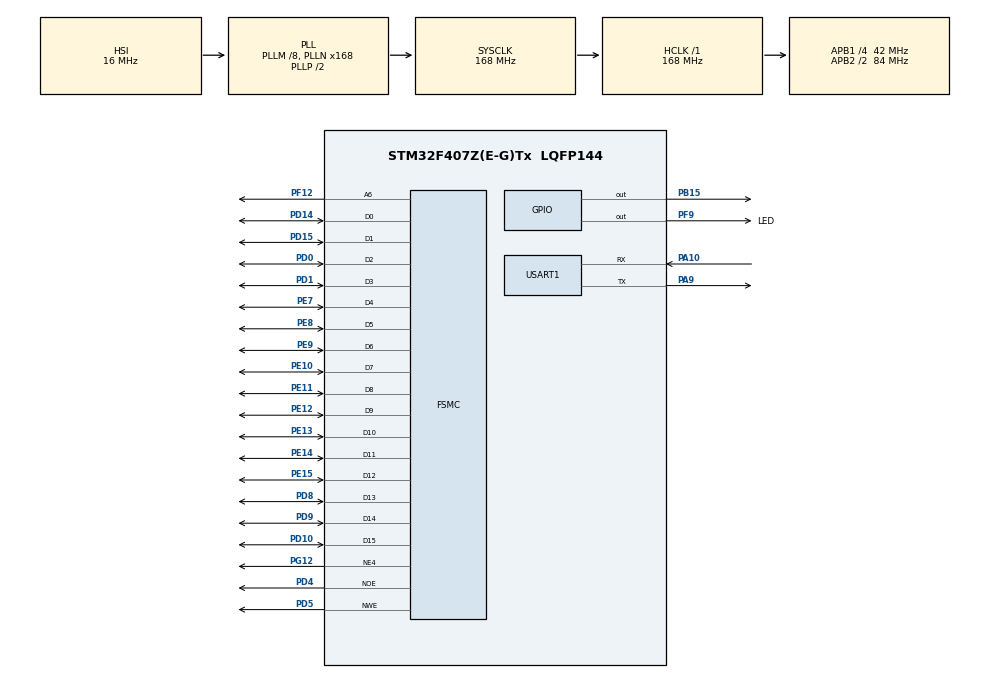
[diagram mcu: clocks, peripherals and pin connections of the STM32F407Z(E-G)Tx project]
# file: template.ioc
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Mcu.Family=STM32F4
PH0-OSC_IN.Signal=RCC_OSC_IN
RCC.CortexFreq_Value=168000000
SH.FSMC_D1_DA1.0=FSMC_D1,16b-d1
SH.FSMC_A6.0=FSMC_A6,A6_1
SH.FSMC_NWE.0=FSMC_NWE,Lcd1
SH.FSMC_D0_DA0.0=FSMC_D0,16b-d1
FSMC.ExtendedBusTurnAroundDuration1=0
PB15.Signal=GPIO_Output
RCC.SYSCLKSource=RCC_SYSCLKSOURCE_PLLCLK
ProjectManager.StackSize=0x400
Dma.USART1_TX.0.Priority=DMA_PRIORITY_LOW
Dma.USART1_TX.0.Direction=DMA_MEMORY_TO_PERIPH
RCC.HCLKFreq_Value=168000000
PD4.Signal=FSMC_NOE
RCC.APB2TimFreq_Value=168000000
PF12.Signal=FSMC_A6
PD0.Signal=FSMC_D2_DA2
PD8.Signal=FSMC_D13_DA13
RCC.AHBFreq_Value=168000000
PH0-OSC_IN.Mode=HSE-External-Oscillator
RCC.HSE_VALUE=25000000
PE13.Signal=FSMC_D10_DA10
SH.FSMC_D14_DA14.0=FSMC_D14,16b-d1
PC14-OSC32_IN.Mode=LSE-External-Oscillator
SH.FSMC_D10_DA10.0=FSMC_D10,16b-d1
PE9.Signal=FSMC_D6_DA6
PA14.Mode=Serial_Wire
SH.FSMC_D6_DA6.0=FSMC_D6,16b-d1
FSMC.BusTurnAroundDuration1=10
Dma.USART1_TX.0.PeriphDataAlignment=DMA_PDATAALIGN_BYTE
PE10.Signal=FSMC_D7_DA7
SH.FSMC_D5_DA5.0=FSMC_D5,16b-d1
SH.FSMC_D4_DA4.0=FSMC_D4,16b-d1
PH1-OSC_OUT.Mode=HSE-External-Oscillator
Mcu.Package=LQFP144
NVIC.DMA2_Stream7_IRQn=true\:0\:0\:false\:false\:true\:false\:true
SH.FSMC_D13_DA13.0=FSMC_D13,16b-d1
PA10.Signal=USART1_RX
Dma.USART1_TX.0.Instance=DMA2_Stream7
Dma.USART1_TX.0.FIFOMode=DMA_FIFOMODE_DISABLE
RCC.APB2CLKDivider=RCC_HCLK_DIV2
SH.FSMC_D3_DA3.0=FSMC_D3,16b-d1
RCC.APB1TimFreq_Value=84000000
SH.FSMC_D2_DA2.0=FSMC_D2,16b-d1
PE7.Signal=FSMC_D4_DA4
NVIC.USART1_IRQn=true\:0\:0\:false\:false\:true\:true\:true
Dma.Request0=USART1_TX
PD15.Signal=FSMC_D1_DA1
PG12.Signal=FSMC_NE4
FSMC.ExtendedAddressSetupTime1=9
PC15-OSC32_OUT.Mode=LSE-External-Oscillator
SH.FSMC_D12_DA12.0=FSMC_D12,16b-d1
Dma.USART1_TX.0.MemInc=DMA_MINC_ENABLE
Dma.USART1_TX.0.PeriphInc=DMA_PINC_DISABLE
PA10.Mode=Asynchronous
FSMC.ExtendedMode1=FSMC_EXTENDED_MODE_ENABLE
PD1.Signal=FSMC_D3_DA3
SH.FSMC_D9_DA9.0=FSMC_D9,16b-d1
PD9.Signal=FSMC_D14_DA14
PD5.Signal=FSMC_NWE
RCC.APB1CLKDivider=RCC_HCLK_DIV4
PC14-OSC32_IN.Signal=RCC_OSC32_IN
SH.FSMC_D8_DA8.0=FSMC_D8,16b-d1
PD10.Signal=FSMC_D15_DA15
PA13.Signal=SYS_JTMS-SWDIO
PA9.Mode=Asynchronous
ProjectManager.TargetToolchain=Makefile
FSMC.DataSetupTime1=60
PA9.Signal=USART1_TX
PF9.GPIO_Label=LED
PE11.Signal=FSMC_D8_DA8
PC15-OSC32_OUT.Signal=RCC_OSC32_OUT
SH.FSMC_D7_DA7.0=FSMC_D7,16b-d1
FSMC.ExtendedDataSetupTime1=8
Dma.USART1_TX.0.Mode=DMA_NORMAL
board=custom
PG12.Mode=NorPsramChipSelect4_1
RCC.VCOOutputFreq_Value=336000000
RCC.APB2Freq_Value=84000000
PE14.Signal=FSMC_D11_DA11
PE15.Signal=FSMC_D12_DA12
PE8.Signal=FSMC_D5_DA5
PH1-OSC_OUT.Signal=RCC_OSC_OUT
PA13.Mode=Serial_Wire
Mcu.Name=STM32F407Z(E-G)Tx
PE12.Signal=FSMC_D9_DA9
PD14.Signal=FSMC_D0_DA0
RCC.48MHZClocksFreq_Value=84000000
RCC.SYSCLKFreq_VALUE=168000000
USART1.VirtualMode=VM_ASYNC
Dma.USART1_TX.0.MemDataAlignment=DMA_MDATAALIGN_BYTE
SH.FSMC_D15_DA15.0=FSMC_D15,16b-d1
PA14.Signal=SYS_JTCK-SWCLK
ProjectManager.HeapSize=0x200
SH.FSMC_D11_DA11.0=FSMC_D11,16b-d1
SH.FSMC_NOE.0=FSMC_NOE,Lcd1
PF9.Signal=GPIO_Output
RCC.HSI_VALUE=16000000
NVIC.PriorityGroup=NVIC_PRIORITYGROUP_4
RCC.PLLM=8
RCC.PLLN=168
RCC.APB1Freq_Value=42000000

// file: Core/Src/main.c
/* USER CODE BEGIN Header */
/**
  ******************************************************************************
  * @file           : main.c
  * @brief          : Main program body
  ******************************************************************************
  * @attention
  *
  * <h2><center>&copy; Copyright (c) 2021 STMicroelectronics.
  * All rights reserved.</center></h2>
  *
  * This software component is licensed by ST under BSD 3-Clause license,
  * the "License"; You may not use this file except in compliance with the
  * License. You may obtain a copy of the License at:
  *                        opensource.org/licenses/BSD-3-Clause
  *
  ******************************************************************************
  */
/* USER CODE END Header */
#include "main.h"
#include "dma.h"
#include "usart.h"
#include "gpio.h"
#include "fsmc.h"

/* USER CODE BEGIN Includes */
#include <stdio.h>
#include <string.h>
#include "lvgl.h"
#include "GT9147.h"
/* USER CODE END Includes */

/* USER CODE BEGIN PD */
#define LVGL_TICK 	5
/* USER CODE END PD */

void SystemClock_Config(void);

int main(void)
{

  /* MCU Configuration--------------------------------------------------------*/

  /* Reset of all peripherals, Initializes the Flash interface and the Systick. */
  HAL_Init();

  /* Configure the system clock */
  SystemClock_Config();

  /* Initialize all configured peripherals */
  MX_GPIO_Init();
  MX_DMA_Init();
  MX_USART1_UART_Init();
  MX_FSMC_Init();
  /* USER CODE BEGIN 2 */
  lv_init();
  lv_port_disp_init();        // 显示器初始化
  lv_port_indev_init();       // 输入设备初始化（如果没有实现就注释掉）
  //lv_port_fs_init();          // 文件系统设备初始化（如果没有实现就注释掉）

  lv_example_btn_1();
  /* USER CODE END 2 */

  /* Infinite loop */
  /* USER CODE BEGIN WHILE */
  while (1)
  {
    lv_tick_inc(LVGL_TICK);
		lv_task_handler();
    HAL_Delay(LVGL_TICK);
    /* USER CODE END WHILE */

  }
}

void SystemClock_Config(void)
{
  RCC_OscInitTypeDef RCC_OscInitStruct = {0};
  RCC_ClkInitTypeDef RCC_ClkInitStruct = {0};

  /** Configure the main internal regulator output voltage
  */
  __HAL_RCC_PWR_CLK_ENABLE();
  __HAL_PWR_VOLTAGESCALING_CONFIG(PWR_REGULATOR_VOLTAGE_SCALE1);
  /** Initializes the RCC Oscillators according to the specified parameters
  * in the RCC_OscInitTypeDef structure.
  */
  RCC_OscInitStruct.OscillatorType = RCC_OSCILLATORTYPE_HSI;
  RCC_OscInitStruct.HSIState = RCC_HSI_ON;
  RCC_OscInitStruct.HSICalibrationValue = RCC_HSICALIBRATION_DEFAULT;
  RCC_OscInitStruct.PLL.PLLState = RCC_PLL_ON;
  RCC_OscInitStruct.PLL.PLLSource = RCC_PLLSOURCE_HSI;
  RCC_OscInitStruct.PLL.PLLM = 8;
  RCC_OscInitStruct.PLL.PLLN = 168;
  RCC_OscInitStruct.PLL.PLLP = RCC_PLLP_DIV2;
  RCC_OscInitStruct.PLL.PLLQ = 4;
  if (HAL_RCC_OscConfig(&RCC_OscInitStruct) != HAL_OK)
  {
    Error_Handler();
  }
  /** Initializes the CPU, AHB and APB buses clocks
  */
  RCC_ClkInitStruct.ClockType = RCC_CLOCKTYPE_HCLK|RCC_CLOCKTYPE_SYSCLK
                              |RCC_CLOCKTYPE_PCLK1|RCC_CLOCKTYPE_PCLK2;
  RCC_ClkInitStruct.SYSCLKSource = RCC_SYSCLKSOURCE_PLLCLK;
  RCC_ClkInitStruct.AHBCLKDivider = RCC_SYSCLK_DIV1;
  RCC_ClkInitStruct.APB1CLKDivider = RCC_HCLK_DIV4;
  RCC_ClkInitStruct.APB2CLKDivider = RCC_HCLK_DIV2;

  if (HAL_RCC_ClockConfig(&RCC_ClkInitStruct, FLASH_LATENCY_5) != HAL_OK)
  {
    Error_Handler();
  }
}

void Error_Handler(void)
{
  __disable_irq();
  while (1)
  {
  }
}

/************************ (C) COPYRIGHT STMicroelectronics *****END OF FILE****/
